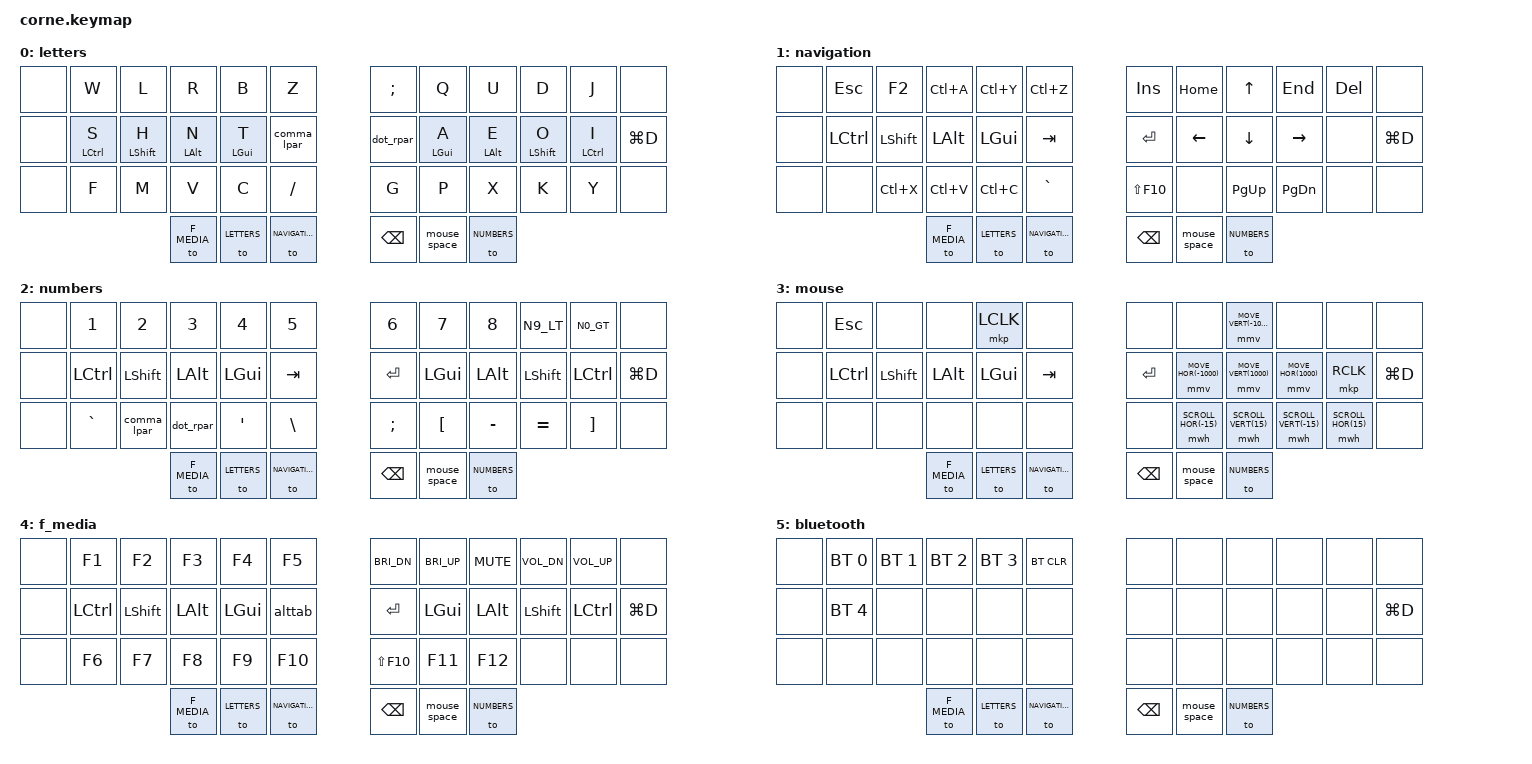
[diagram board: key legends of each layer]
/* f19 to 19.2
/*
 * Copyright (c) 2020 The ZMK Contributors

 * SPDX-License-Identifier: MIT
 */

#include <behaviors.dtsi>
#include <dt-bindings/zmk/keys.h>
//#include <dt-bindings/zmk/outputs.h>
#include <dt-bindings/zmk/bt.h>
#include <dt-bindings/zmk/mouse.h>

//&out OUT_BLE //prioritises bluetooth over USB

#define LETTERS     0
#define NAVIGATION  1
#define NUMBERS     2
#define MOUSE       3
#define F_MEDIA     4
#define BLUETOOTH   5


&sk {
     quick-release;
//Enough time for me to use sticky modifiers
//     release-after-ms = <2000>;
};


// Added period and forward slash to default continue list
&caps_word {
continue-list = <UNDERSCORE BSPC MINUS PERIOD SLASH>;
};

// Mouse movement and mouse wheel speed and acceleration settings
&mmv {    
        time-to-max-speed-ms = <250>;
        acceleration-exponent=<1>;
};
&mwh {    
        time-to-max-speed-ms = <0>;
        acceleration-exponent=<1>;
};


/ {
// Key Positions Index for Combos
// ________________________________________________________________________________________________________
// |   0  |   1  |   2  |   3  |   4  |   5  |                  |   6  |   7  |   8  |   9  |  10  |  11  |
// |  12  |  13  |  14  |  15  |  16  |  17  |                  |  18  |  19  |  20  |  21  |  22  |  23  |
// |  24  |  25  |  26  |  27  |  28  |  29  |                  |  30  |  31  |  32  |  33  |  34  |  35  |
//                             |  36  |  37  |  38  |    |  39  |  40  |  41  |
	
        combos {
            compatible = "zmk,combos";
                combo_shift {
                        timeout-ms = <20>;
                        key-positions = <2 3>;
                        layers = <LETTERS NUMBERS>;
                        bindings = <&sk LSHFT>;                      
                };

                combo_enter {
                        timeout-ms = <20>;
                        key-positions = <8 9>;
                        bindings = <&kp ENTER>;                      
                };

                combo_caps_word {
                        timeout-ms = <20>;
                        key-positions = <2 3 4>;
                        bindings = <&caps_word>;                      
                };

                // workaround as default &kp C_AL_LOCK function does not work in Windows
                combo_lock_computer {
                        timeout-ms = <30>;
                        key-positions = <8 9 10>;
                        bindings = <&kp LG(L)>;                      
                };

                combo_reset_keyboard {
                        timeout-ms = <20>;
                        key-positions = <18 19>;
                        layers = <BLUETOOTH>;
                        bindings = <&reset>;                      
                };

                combo_bootloader {
                        timeout-ms = <20>;
                        key-positions = <30 31>;
                        layers = <BLUETOOTH>;
                        bindings = <&bootloader>;                      
                };

                combo_bluetooth_layer {
                        timeout-ms = <20>;
                        key-positions = <30 31 32>;
                        bindings = <&to BLUETOOTH>;                      
                };

        };

        macros {
             //Macros to emulate &mo behaviour
                //back to numbers
                alttab: alttab {
                        label = "ZM_alttab";
                        compatible = "zmk,behavior-macro";
                        #binding-cells = <0>;
                        wait-ms = <0>;
                        bindings
                                = <&kp LALT  &kp TAB>;
                        };

                /*
                mo_nav_num: mo_nav_num {
                        label = "ZM_mo_nav_num";
                        compatible = "zmk,behavior-macro";
                        #binding-cells = <0>;
                        wait-ms = <0>;
                        bindings
                                = <&macro_press &to LETTERS &to NAVIGATION>
                                , <&macro_pause_for_release>
                                , <&macro_release &to LETTERS>
                                , <&to LETTERS &to NUMBERS>;
                        };

                //back to mouse
                mo_nav_mou: mo_nav_mou {
                        label = "ZM_mo_nav_mou";
                        compatible = "zmk,behavior-macro";
                        #binding-cells = <0>;
                        wait-ms = <0>;
                        bindings
                                = <&macro_press &to LETTERS &to NAVIGATION>
                                , <&macro_pause_for_release>
                                , <&macro_release &to LETTERS>
                                , <&to LETTERS &to MOUSE>;
                        };

                //back to navigation
                mo_nav_nav: mo_nav_nav {
                        label = "ZM_mo_nav_nav";
                        compatible = "zmk,behavior-macro";
                        #binding-cells = <0>;
                        wait-ms = <0>;
                        bindings
                                = <&macro_press &to LETTERS &to NAVIGATION>
                                , <&macro_pause_for_release>
                                , <&macro_release &to LETTERS>
                                , <&to LETTERS &to NAVIGATION>;

                        };
                */
       
        };



        behaviors {
        
        //Mod-Morphs
                //Mod-Morph to input 9 or (with shift) < in HALMAK layout
                N9_LT: N9_LT {
                        compatible = "zmk,behavior-mod-morph";
                        label = "N9_LT";
                        #binding-cells = <0>;
                        bindings = <&kp N9>, <&kp LESS_THAN>;
                        mods = <(MOD_LSFT)>;
                };
                
                //Mod-Morph to input 0 or (with shift) > in HALMAK layout
                N0_GT: N0_GT {
                        compatible = "zmk,behavior-mod-morph";
                        label = "N0_GT";
                        #binding-cells = <0>;
                        bindings = <&kp N0>, <&kp GREATER_THAN>;
                        mods = <(MOD_LSFT)>;
                };
                
                //Mod-Morph to input comma or (with shift) open parenthesis in HALMAK layout
                comma_lpar: comma_lpar {
                        compatible = "zmk,behavior-mod-morph";
                        label = "COMMA_LPAR";
                        #binding-cells = <0>;
                        bindings = <&kp COMMA>, <&kp LPAR>;
                        mods = <(MOD_LSFT)>;
                };
               
                //Mod-Morph to input period or (with shift) close parenthesis in HALMAK layout, and Hold = ENTER
                dot_rpar: dot_rpar {
                        compatible = "zmk,behavior-mod-morph";
                        label = "DOT_RPAR";
                        #binding-cells = <0>;
                        bindings = <&hota ENTER PERIOD>, <&kp RPAR>;
                        mods = <(MOD_LSFT)>;
                };
               
                //Mod-Morph to input % or (with shift) /
                percent_divide: percent_divide {
                        compatible = "zmk,behavior-mod-morph";
                        label = "PERCENT_DIVIDE";
                        #binding-cells = <0>;
                        bindings = <&kp PERCENT>, <&kp KP_DIVIDE>;
                        mods = <(MOD_LSFT)>;
                };


        //Hold_Tap

                /*
                mo_to: mo_to {
                        compatible = "zmk,behavior-hold-tap";
                        label = "MO_TO";
                        #binding-cells = <2>;
                        flavor = "hold-preferred";
                        tapping-term-ms = <150>;
                        quick-tap-ms = <300>;                        
                        bindings = <&mo>, <&to>;
                };

                mo_nav_num_to: mo_nav_num_to {
                        compatible = "zmk,behavior-hold-tap";
                        label = "mo_nav_num_TO";
                        #binding-cells = <2>;
                        flavor = "hold-preferred";
                        tapping-term-ms = <150>;
                        quick-tap-ms = <300>;                        
                        bindings = <&mo_nav_num>, <&to>;
                };

                mo_nav_mou_to: mo_nav_mou_to {
                        compatible = "zmk,behavior-hold-tap";
                        label = "mo_nav_mou_TO";
                        #binding-cells = <2>;
                        flavor = "hold-preferred";
                        tapping-term-ms = <150>;
                        quick-tap-ms = <300>;                        
                        bindings = <&mo_nav_mou>, <&to>;
                };

                mo_nav_nav_to: mo_nav_nav_to {
                        compatible = "zmk,behavior-hold-tap";
                        label = "mo_nav_nav_TO";
                        #binding-cells = <2>;
                        flavor = "hold-preferred";
                        tapping-term-ms = <150>;
                        quick-tap-ms = <300>;                        
                        bindings = <&mo_nav_nav>, <&to>;
                };
                */

                hota: holdtap1 {
                        compatible = "zmk,behavior-hold-tap";
                        label = "HOLDTAP1";
                        #binding-cells = <2>;
                        flavor = "hold-preferred";
                        tapping-term-ms = <150>;
                        quick-tap-ms = <280>;                        
                        bindings = <&kp>, <&kp>;
                };

                
                lok1: layer_or_keypress1 {
                        compatible = "zmk,behavior-hold-tap";
                        label = "LAYER_OR_KEYPRESS1";
                        #binding-cells = <2>;
                        flavor = "hold-preferred";
                        tapping-term-ms = <100>;
                        bindings = <&mo>, <&kp>;
                };
                

                lok2: layer_or_keypress2 {
                        compatible = "zmk,behavior-hold-tap";
                        label = "LAYER_OR_KEYPRESS2";
                        #binding-cells = <2>;
                        flavor = "hold-preferred";
                        tapping-term-ms = <100>;
                        bindings = <&mo>, <&kp>;
                };

        //Tap-Dance

                //Press Go to Backspace | Hold Momentary Numbers | Tap-Dance Numbers
                /*
                num_bspc: num_bspc {
                        compatible = "zmk,behavior-tap-dance";
                        label = "NUM_BSPC";
                        #binding-cells = <0>;
                        tapping-term-ms = <150>;
                        bindings = <&lok1 NUMBERS BSPC>, <&to NUMBERS>; 
                };
                */

                //Press Go to Space | Hold Momentary Mouse | Tap-Dance Space | Tap-Dance Mouse --> two taps = space, three taps goes to mouse layer
                mouse_space: mouse_space {
                        compatible = "zmk,behavior-tap-dance";
                        label = "MOUSE_SPACE";
                        #binding-cells = <0>;
                        tapping-term-ms = <200>;
                        bindings = <&lok2 MOUSE SPACE>, <&kp SPACE>, <&to MOUSE>;
                };


// Key Positions Index for Combos
// ________________________________________________________________________________________________________
// |   0  |   1  |   2  |   3  |   4  |   5  |                  |   6  |   7  |   8  |   9  |  10  |  11  |
// |  12  |  13  |  14  |  15  |  16  |  17  |                  |  18  |  19  |  20  |  21  |  22  |  23  |
// |  24  |  25  |  26  |  27  |  28  |  29  |                  |  30  |  31  |  32  |  33  |  34  |  35  |
//                             |  36  |  37  |  38  |    |  39  |  40  |  41  |
        //Home-row Mods
                /* left-hand positional HRMs */
                hml: hml {
                        compatible = "zmk,behavior-hold-tap";
                        label = "HML";
                        #binding-cells = <2>;
                        flavor = "balanced";
                        tapping-term-ms = <280>;
                        quick-tap-ms = <175>;                // double tapping same key allows for repeating
                        global-quick-tap-ms = <150>;         // without PR #1387 use global-quick-tap instead
                        bindings = <&kp>, <&kp>;
                        hold-trigger-key-positions = <6 7 8 9 10 11 18 19 20 21 22 23 30 31 32 33 34 35 36 37 38 39 40 41>;
                        hold-trigger-on-release;             // requires PR #1423
                };

                /* right-hand positional HRMs */
                hmr: hmr {
                        compatible = "zmk,behavior-hold-tap";
                        label = "HMR";
                        #binding-cells = <2>;
                        flavor = "balanced";
                        tapping-term-ms = <280>;
                        quick-tap-ms = <175>;                // double tapping same key allows for repeating
                        global-quick-tap-ms = <150>;         // without PR #1387 use global-quick-tap instead
                        bindings = <&kp>, <&kp>;
                        hold-trigger-key-positions = <0 1 2 3 4 5 12 13 14 15 16 17 24 25 26 27 28 29 36 37 38 39 40 41>;
                        hold-trigger-on-release;             // requires PR #1423
                };

        };
	

        keymap {
                compatible = "zmk,keymap";


                letters {
//                 LETTERS
//                _________________________________________________________________________________________
//              |    |  w  |  l  |  r  |  b   |  z   |             | ;: |  q  |  u  |  d  |  j  |    |
//Combo         |    |     |   Shift   |      |      |             |    |     |   Enter   |     |    |
//Combo         |    |     |   Caps Words     |      |             |    |     |  Lock Computer  |    |
//
//              |    |  s  |  h  |  n  |  t   |  ,(  |             | .)  |  a  |  e  |  o  |  i  |    |
//HR Mods       |    |Ctrl |Shift| Alt |  Win |Tab   |             |Enter|Win  | Alt |Shift|Ctrl |    |

//              |    |  f  |  m  |  v  |  c   |  /?  |             | g  |  p  |  x  |  k  |  y  |    |
//                                     |F_Med | Let  | Nav | | Bspc|Space/Mouse|Num|

                                        bindings = <
                &none   &kp W         &kp L          &kp R         &kp B        &kp Z                      &kp SEMICOLON        &kp Q        &kp U         &kp D        &kp J  &none
                &none   &hml LCTL S   &hml LSHIFT H  &hml LALT N   &hml LGUI T  &comma_lpar                &dot_rpar      &hmr LGUI A  &hmr LALT E  &hmr LSHIFT O &hmr LCTL I  &kp LG(D)
                &none   &kp F         &kp M          &kp V         &kp C        &kp SLASH                  &kp G                &kp P        &kp X         &kp K        &kp Y  &none   
                                                        &to F_MEDIA  &to LETTERS   &to NAVIGATION    &kp BSPC &mouse_space &to NUMBERS
                        >;
                };

                navigation {
//              /* NAVIGATION
//              _______________________________________________________________________________________________________
//              |    |Esc   |F2    |Ctrl-A| Ctrl-Y |  Ctrl-Z  |             |Insert  |Home     |  Up  |End     |Delete |    |
//              |    |Ctrl  |Shift | Alt  |  Tab   |   Win    |             |Enter   |Left     | Down |Right   |       |    |
//              |    |Ctrl-Z|Ctrl-X|Ctrl-V| Ctrl-C |    `     |             |DropDown|         |PageUp|PageDown|       |    |
//                                        | F_Media|   Let    |Nav|    |Bspc|Space/Mouse|Num|

                        bindings = <
                        &none   &kp ESC    &kp F2     &kp LC(A)  &kp LC(Y)   &kp LC(Z)                 &kp INS &kp HOME   &kp UP    &kp END    &kp DEL    &none  
                        &none   &kp LCTRL  &kp LSHIFT &kp LALT   &kp LGUI    &kp TAB                   &kp ENTER   &kp LEFT   &kp DOWN  &kp RIGHT  &none      &kp LG(D)   
                        &none   &none      &kp LC(X)  &kp LC(V)  &kp LC(C)   &kp GRAVE                 &kp LS(F10) &none  &kp PG_UP &kp PG_DN  &none      &none   
                                                       &to F_MEDIA  &to LETTERS   &to NAVIGATION    &kp BSPC &mouse_space &to NUMBERS
                        >;
                };

                numbers {
//               NUMBERS     
//              __________________________________________________________________________________________
//              |     | 1 ! | 2 @ | 3 # | 4 $  |  5 %    |             | 6 ^ | 7 & | 8 * | 9 < | 0 > |    |
//              |     |     |   Shift   |      |         |             |     |     |     |     |     |    |
//
//              |     |Ctrl |Shift| Alt |  Win |Tab |                  |Enter|Win  | Alt |Shift|Ctrl |    |
//              |     | ` ~ | , ( | . ) | ' "  |  \ |                  | ; : | [ { | - _ | = + | ] } |    |
//                                      |F_Media|Let|Nav|         |Bspc|Space/Mouse|Num|

                        bindings = <
                        &none   &kp N1          &kp N2         &kp N3         &kp N4         &kp N5                &kp N6    &kp N7    &kp N8     &N9_LT      &N0_GT   &none   
                        &none   &kp LCTRL       &kp LSHIFT     &kp LALT       &kp LGUI       &kp TAB               &kp ENTER   &kp LGUI  &kp LALT &kp LSHIFT  &kp LCTRL   &kp LG(D)    
                        &none   &kp GRAVE       &comma_lpar    &dot_rpar      &kp SQT        &kp BACKSLASH         &kp SEMI  &kp LBKT  &kp MINUS  &kp EQUAL   &kp RBKT &none   
                                                                    &to F_MEDIA  &to LETTERS   &to NAVIGATION    &kp BSPC &mouse_space &to NUMBERS
                        >;
                };

                mouse {
//               MOUSE       
//              ____________________________________________________________________________________________________________
//              |    |    |     |   |LeftClick|         |             |     |          |MouseUp  |          |           |    |
//              |    |Ctrl|Shift|Alt|  Win    |   Tab   |             |Enter|MouseLeft |MouseDown|MouseRight|RightClick |    |
//              |    |    |     |   |         |         |             |     |ScrollLeft|ScrollUp |ScrollDown|ScrollRight|    |
//                                          |F_Media|Let|Nav|    |Bspc|Space/Mouse|Num|

                        bindings = <
                        &none   &kp ESC    &none      &none      &mkp LCLK   &none               &none     &none                 &mmv MOVE_VERT(-1000)  &none                &none                &none   
                        &none   &kp LCTRL  &kp LSHIFT &kp LALT   &kp LGUI    &kp TAB             &kp ENTER &mmv MOVE_HOR(-1000)  &mmv MOVE_VERT(1000)   &mmv MOVE_HOR(1000)    &mkp RCLK            &kp LG(D)   
                        &none   &none      &none      &none      &none       &none               &none     &mwh SCROLL_HOR(-15)  &mwh SCROLL_VERT(15)   &mwh SCROLL_VERT(-15)  &mwh SCROLL_HOR(15)  &none   
                                                    &to F_MEDIA  &to LETTERS   &to NAVIGATION    &kp BSPC &mouse_space &to NUMBERS
                        >;
                };

                f_media {
//               F_MEDIA     
//              __________________________________________________________________________________________________________
//              |    |  F1  |  F2  |  F3  |  F4  |  F5     |             |BrightDown|BrightUp|VolMute|VolDown|VolUp |    |
//              |    |Ctrl  |Shift |  Alt |  Win |  Tab    |             |Enter     |Win     | Alt   |Shift  |Ctrl  |    |
//              |    |  F6  |  F7  |  F8  |  F9  |  F10    |             |DropDown  |  F11   |  F12  |       |      |    |
//                                        |F_Media|   Let  |Nav|    |Bspc|Space/Mouse|Num|

                        bindings = <
                        &none   &kp F1     &kp F2     &kp F3     &kp F4      &kp F5                &kp C_BRI_DN  &kp C_BRI_UP  &kp C_MUTE  &kp C_VOL_DN  &kp C_VOL_UP  &none   
                        &none   &kp LCTRL  &kp LSHIFT &kp LALT   &kp LGUI    &alttab              &kp ENTER     &kp LGUI      &kp LALT  &kp LSHIFT      &kp LCTRL     &kp LG(D)   
                        &none   &kp F6     &kp F7     &kp F8     &kp F9      &kp F10               &kp LS(F10)   &kp F11       &kp F12     &none         &none         &none   
                                                    &to F_MEDIA  &to LETTERS   &to NAVIGATION    &kp BSPC &mouse_space &to NUMBERS
                        >;
                };

                bluetooth {
//               BLUETOOTH   
//              ___________________________________________________________________________________
//              |    |BT1 |BT2 |BT3 |BT4   |ResetActive BT|        |    |     |    |    |    |    |
//              |    |BT5 |    |    |      |              |        |    |     |    |    |    |    |
//              |    |    |    |    |      |              |        |  Reset   |    |    |    |    |
//
//              |    |    |    |    |      |              |        |    |     |    |    |    |    |
//              |    |    |    |    |      |              |        |Bootloader|    |    |    |    |
//
//                                      |F_Media|Let|Nav|         |Bspc|Space/Mouse|Num|

                        bindings = <
                        &none   &bt BT_SEL 0    &bt BT_SEL 1  &bt BT_SEL 2  &bt BT_SEL 3  &bt BT_CLR              &none   &none   &none   &none   &none   &none   
                        &none   &bt BT_SEL 4    &none         &none         &none         &none                   &none   &none   &none   &none   &none   &kp LG(D)
                        &none   &none           &none         &none         &none         &none                   &none   &none   &none   &none   &none   &none   
                                                        &to F_MEDIA  &to LETTERS   &to NAVIGATION    &kp BSPC &mouse_space &to NUMBERS
                        >;
                };


        };
};
